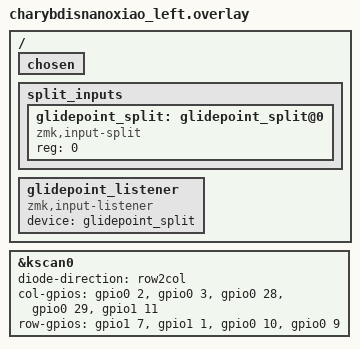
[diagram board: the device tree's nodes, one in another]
/*
 * Copyright (c) 2020 Pete Johanson
 *
 * SPDX-License-Identifier: MIT
 */

#include "charybdisnanoxiao.dtsi"

#include "charybdisnanoxiao-pinctrl_left.dtsi"

&kscan0 {
  diode-direction = "row2col";
  col-gpios
		= <&gpio0 2 (GPIO_ACTIVE_HIGH | GPIO_PULL_DOWN)>    //Col0
		, <&gpio0 3 (GPIO_ACTIVE_HIGH | GPIO_PULL_DOWN)>    //Col1
		, <&gpio0 28 (GPIO_ACTIVE_HIGH | GPIO_PULL_DOWN)>   //Col2
		, <&gpio0 29 (GPIO_ACTIVE_HIGH | GPIO_PULL_DOWN)>   //Col3
		, <&gpio1 11 (GPIO_ACTIVE_HIGH | GPIO_PULL_DOWN)>   //Col4
		;

  row-gpios
    = <&gpio1 7  GPIO_ACTIVE_HIGH>     //Row0
    , <&gpio1 1 GPIO_ACTIVE_HIGH>     //Row1
    , <&gpio0 10 GPIO_ACTIVE_HIGH>    //Row2
    , <&gpio0 9  GPIO_ACTIVE_HIGH>    //Row3
    ;

};

/ {
    chosen {
        //zephyr,display = &oled_128x32;
    };
    split_inputs {
        #address-cells = <1>;
        #size-cells = <0>;
        glidepoint_split: glidepoint_split@0{
            compatible = "zmk,input-split";
            reg = <0>;
            //status = "okay";
        };
    };

    glidepoint_listener: glidepoint_listener {
        compatible = "zmk,input-listener";
        status = "okay";
        device = <&glidepoint_split>;
    };
};


